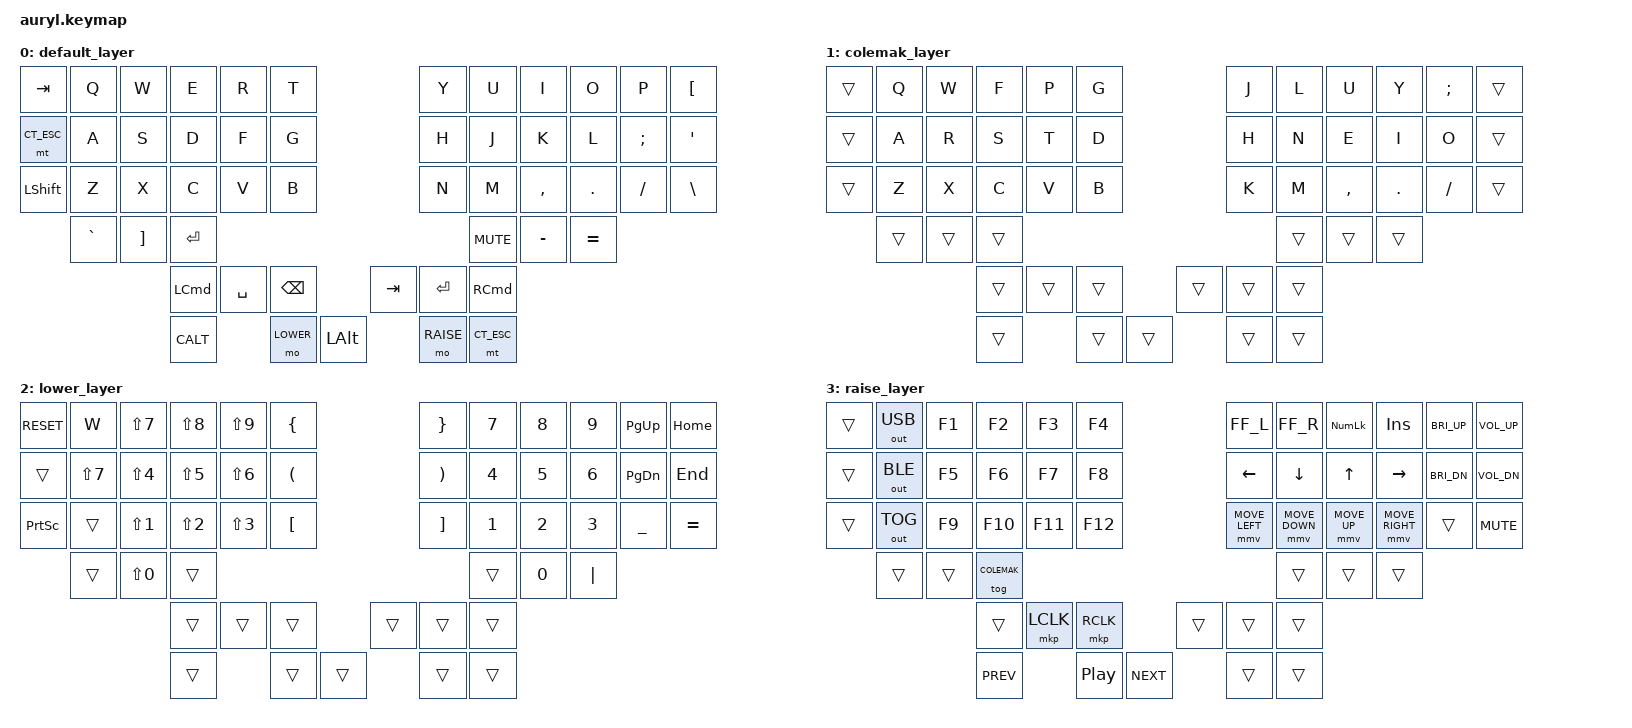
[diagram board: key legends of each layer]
/*
 * Copyright (c) 2020 The ZMK Contributors
 *
 * SPDX-License-Identifier: MIT
 */

#include <behaviors.dtsi>
#include <dt-bindings/zmk/keys.h>
#include <dt-bindings/zmk/bt.h>
#include <dt-bindings/zmk/mouse.h>
#include <dt-bindings/zmk/outputs.h>
// #include <dt-bindings/zmk/trackball_pim447.h>

#define DEFAULT 0
#define COLEMAK 1
#define LOWER 2
#define RAISE 3

#define CT_ESC LCTRL ESC
#define HYPER LC(LA(LCMD))
#define FF_L LG(LA(LEFT))
#define FF_R LG(LA(RIGHT))
#define CALT LA(LCTRL)

/ {
        keymap {
                compatible = "zmk,keymap";

                default_layer {
                        bindings = <
   &kp TAB    &kp Q &kp W &kp E &kp R &kp T                                 &kp Y &kp U  &kp I     &kp O   &kp P    &kp LBKT
   &mt CT_ESC &kp A &kp S &kp D &kp F &kp G                                 &kp H &kp J  &kp K     &kp L   &kp SEMI &kp SQT
   &kp LSHFT  &kp Z &kp X &kp C &kp V &kp B                                 &kp N &kp M  &kp COMMA &kp DOT &kp FSLH &kp BSLH
                 &kp GRAVE &kp RBKT          &kp ENTER                 &kp C_MUTE         &kp MINUS &kp EQUAL
                             &kp LCMD  &kp SPACE &kp BSPC     &kp TAB &kp ENTER &kp RCMD 
                             &kp CALT  &mo LOWER &kp LALT             &mo RAISE &mt CT_ESC 
                        >;
                        sensor-bindings = <&inc_dec_kp C_VOL_DN C_VOL_UP &inc_dec_kp PG_DN PG_UP>;
                };

                colemak_layer {
                        bindings = <
   &trans &kp Q &kp W &kp F &kp P &kp G                                 &kp J &kp L  &kp U     &kp Y   &kp SEMI &trans
   &trans &kp A &kp R &kp S &kp T &kp D                                 &kp H &kp N  &kp E     &kp I   &kp O    &trans
   &trans &kp Z &kp X &kp C &kp V &kp B                                 &kp K &kp M  &kp COMMA &kp DOT &kp FSLH &trans
                 &trans &trans           &trans                     &trans           &trans &trans 
                                &trans &trans &trans              &trans &trans &trans      
                                &trans &trans &trans                     &trans &trans
                        >;
                        sensor-bindings = <&inc_dec_kp PG_DN PG_UP &inc_dec_kp C_VOL_DN C_VOL_UP>; 
                };

                lower_layer {
                        bindings = <
   &kp C_RESET &kp W      &kp LS(N7) &kp LS(N8) &kp LS(N9) &kp LBRC                         &kp RBRC &kp N7 &kp N8 &kp N9 &kp PG_UP &kp HOME
   &trans      &kp LS(N7) &kp LS(N4) &kp LS(N5) &kp LS(N6) &kp LPAR                         &kp RPAR &kp N4 &kp N5 &kp N6 &kp PG_DN &kp END
   &kp PSCRN   &trans     &kp LS(N1) &kp LS(N2) &kp LS(N3) &kp LBKT                         &kp RBKT &kp N1 &kp N2 &kp N3 &kp UNDER &kp EQUAL
                          &trans     &kp LS(N0)              &trans                    &trans        &kp N0 &kp PIPE
                                &trans &trans &trans              &trans &trans &trans      
                                &trans &trans &trans                     &trans &trans
                        >;
                        sensor-bindings = <&inc_dec_kp LC(LS(TAB)) LC(TAB) &inc_dec_kp C_VOL_DN C_VOL_UP>;
                        // sensor-bindings = <&inc_dec_kp C_VOL_DN C_VOL_UP  &inc_dec_kp PG_UP PG_DN>;
                };

                raise_layer {
                        bindings = <
   &trans    &out OUT_USB &kp F1 &kp F2  &kp F3  &kp F4                        &kp FF_L &kp FF_R &kp KP_NUM &kp INS   &kp C_BRI_UP &kp C_VOL_UP
   &trans    &out OUT_BLE &kp F5 &kp F6  &kp F7  &kp F8                        &kp LEFT &kp DOWN &kp UP     &kp RIGHT &kp C_BRI_DN &kp C_VOL_DN
   &trans    &out OUT_TOG &kp F9 &kp F10 &kp F11 &kp F12                       &mmv MOVE_LEFT &mmv MOVE_DOWN &mmv MOVE_UP &mmv MOVE_RIGHT &trans &kp C_MUTE
                    &trans  &trans                &tog COLEMAK                &trans             &trans &trans
                                &trans &mkp LCLK &mkp RCLK         &trans &trans &trans      
                                &kp C_PREV &kp C_PP &kp C_NEXT           &trans &trans      
                        >;
                        sensor-bindings = <&inc_dec_kp LA(RIGHT) LA(LEFT) &inc_dec_kp PG_UP PG_DN>;
                };
        };
};
